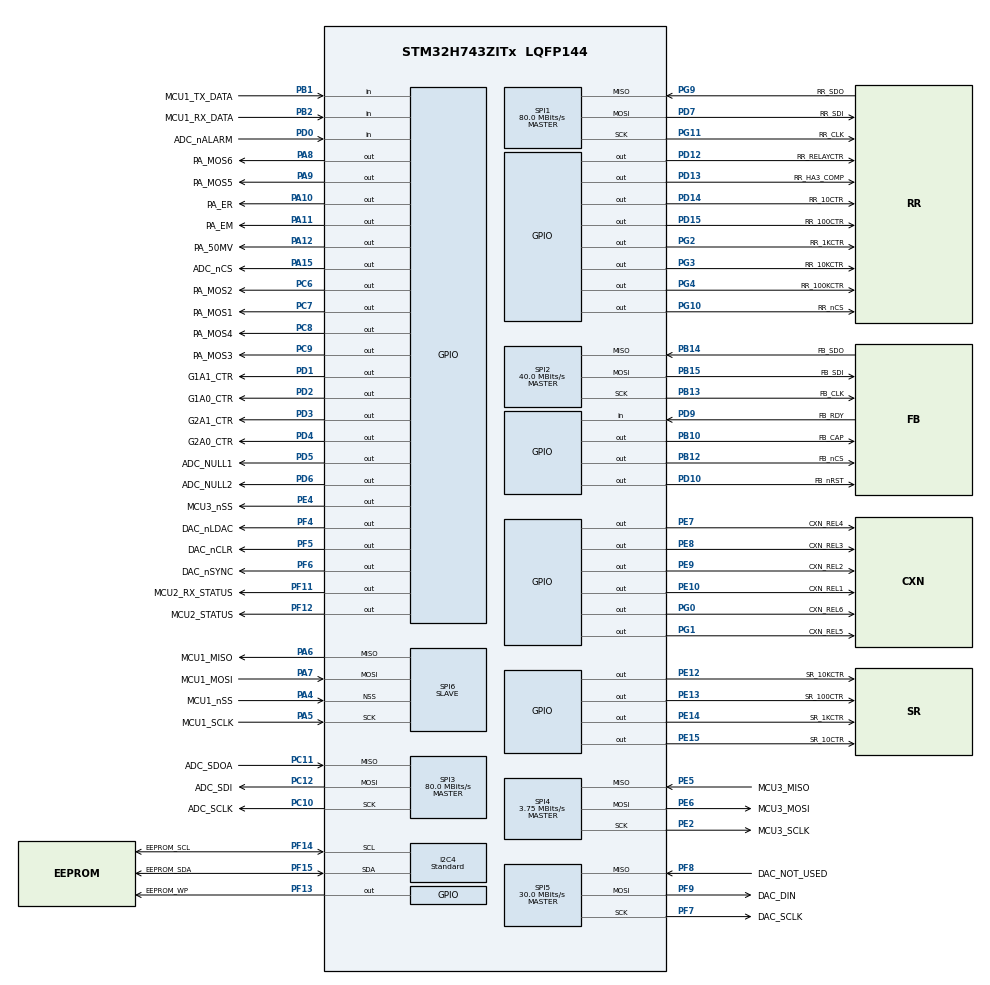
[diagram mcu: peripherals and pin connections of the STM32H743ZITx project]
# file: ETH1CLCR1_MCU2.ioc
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I2C4.I2C_Speed_Mode=I2C_Standard
I2C4.Timing=0x307075B1
Mcu.Family=STM32H7
Mcu.Name=STM32H743ZITx
Mcu.Package=LQFP144
NVIC.PriorityGroup=NVIC_PRIORITYGROUP_4
NVIC.SPI6_IRQn=true\:1\:0\:true\:false\:true\:true\:true
PA10.GPIO_Label=PA_ER
PA10.GPIO_Speed=GPIO_SPEED_FREQ_HIGH
PA10.Signal=GPIO_Output
PA11.GPIO_Label=PA_EM
PA11.GPIO_Speed=GPIO_SPEED_FREQ_HIGH
PA11.Signal=GPIO_Output
PA12.GPIO_Label=PA_50MV
PA12.GPIO_Speed=GPIO_SPEED_FREQ_HIGH
PA12.Signal=GPIO_Output
PA13\ (JTMS/SWDIO).Mode=Serial_Wire
PA13\ (JTMS/SWDIO).Signal=DEBUG_JTMS-SWDIO
PA14\ (JTCK/SWCLK).Mode=Serial_Wire
PA14\ (JTCK/SWCLK).Signal=DEBUG_JTCK-SWCLK
PA15\ (JTDI).GPIO_Label=ADC_nCS
PA15\ (JTDI).GPIO_Speed=GPIO_SPEED_FREQ_VERY_HIGH
PA15\ (JTDI).PinState=GPIO_PIN_SET
PA15\ (JTDI).Signal=GPIO_Output
PA4.GPIO_Label=MCU1_nSS
PA4.GPIO_Speed=GPIO_SPEED_FREQ_HIGH
PA4.Mode=NSS_Signal_Hard_Input
PA4.Signal=SPI6_NSS
PA5.GPIO_Label=MCU1_SCLK
PA5.GPIO_PuPd=GPIO_NOPULL
PA5.GPIO_Speed=GPIO_SPEED_FREQ_HIGH
PA5.Mode=Full_Duplex_Slave
PA5.Signal=SPI6_SCK
PA6.GPIO_Label=MCU1_MISO
PA6.GPIO_Speed=GPIO_SPEED_FREQ_HIGH
PA6.Mode=Full_Duplex_Slave
PA6.Signal=SPI6_MISO
PA7.GPIO_Label=MCU1_MOSI
PA7.GPIO_Speed=GPIO_SPEED_FREQ_HIGH
PA7.Mode=Full_Duplex_Slave
PA7.Signal=SPI6_MOSI
PA8.GPIO_Label=PA_MOS6
PA8.GPIO_Speed=GPIO_SPEED_FREQ_HIGH
PA8.Signal=GPIO_Output
PA9.GPIO_Label=PA_MOS5
PA9.GPIO_Speed=GPIO_SPEED_FREQ_HIGH
PA9.Signal=GPIO_Output
PB1.GPIO_Label=MCU1_TX_DATA
PB1.GPIO_PuPd=GPIO_PULLUP
PB1.Signal=GPIO_Input
PB10.GPIO_Label=FB_CAP
PB10.GPIO_Speed=GPIO_SPEED_FREQ_HIGH
PB10.Signal=GPIO_Output
PB12.GPIO_Label=FB_nCS
PB12.GPIO_Speed=GPIO_SPEED_FREQ_VERY_HIGH
PB12.PinState=GPIO_PIN_SET
PB12.Signal=GPIO_Output
PB13.GPIO_Label=FB_CLK
PB13.GPIO_Speed=GPIO_SPEED_FREQ_LOW
PB13.Mode=Full_Duplex_Master
PB13.Signal=SPI2_SCK
PB14.GPIO_Label=FB_SDO
PB14.GPIO_Speed=GPIO_SPEED_FREQ_LOW
PB14.Mode=Full_Duplex_Master
PB14.Signal=SPI2_MISO
PB15.GPIO_Label=FB_SDI
PB15.GPIO_Speed=GPIO_SPEED_FREQ_LOW
PB15.Mode=Full_Duplex_Master
PB15.Signal=SPI2_MOSI
PB2.GPIO_Label=MCU1_RX_DATA
PB2.GPIO_PuPd=GPIO_PULLUP
PB2.Signal=GPIO_Input
PC10.GPIO_Label=ADC_SCLK
PC10.GPIO_PuPd=GPIO_PULLUP
PC10.GPIO_Speed=GPIO_SPEED_FREQ_MEDIUM
PC10.Mode=Full_Duplex_Master
PC10.Signal=SPI3_SCK
PC11.GPIO_Label=ADC_SDOA
PC11.GPIO_PuPd=GPIO_PULLUP
PC11.GPIO_Speed=GPIO_SPEED_FREQ_HIGH
PC11.Mode=Full_Duplex_Master
PC11.Signal=SPI3_MISO
PC12.GPIO_Label=ADC_SDI
PC12.GPIO_PuPd=GPIO_PULLUP
PC12.GPIO_Speed=GPIO_SPEED_FREQ_HIGH
PC12.Mode=Full_Duplex_Master
PC12.Signal=SPI3_MOSI
PC6.GPIO_Label=PA_MOS2
PC6.GPIO_Speed=GPIO_SPEED_FREQ_HIGH
PC6.Signal=GPIO_Output
PC7.GPIO_Label=PA_MOS1
PC7.GPIO_Speed=GPIO_SPEED_FREQ_HIGH
PC7.Signal=GPIO_Output
PC8.GPIO_Label=PA_MOS4
PC8.GPIO_Speed=GPIO_SPEED_FREQ_HIGH
PC8.Signal=GPIO_Output
PC9.GPIO_Label=PA_MOS3
PC9.GPIO_Speed=GPIO_SPEED_FREQ_HIGH
PC9.Signal=GPIO_Output
PD0.GPIO_Label=ADC_nALARM
PD0.Signal=GPIO_Input
PD1.GPIO_Label=G1A1_CTR
PD1.GPIO_Speed=GPIO_SPEED_FREQ_HIGH
PD1.Signal=GPIO_Output
PD10.GPIO_Label=FB_nRST
PD10.GPIO_Speed=GPIO_SPEED_FREQ_HIGH
PD10.PinState=GPIO_PIN_SET
PD10.Signal=GPIO_Output
PD12.GPIO_Label=RR_RELAYCTR
PD12.GPIO_Speed=GPIO_SPEED_FREQ_HIGH
PD12.Signal=GPIO_Output
PD13.GPIO_Label=RR_HA3_COMP
PD13.GPIO_Speed=GPIO_SPEED_FREQ_HIGH
PD13.Signal=GPIO_Output
PD14.GPIO_Label=RR_10CTR
PD14.GPIO_Speed=GPIO_SPEED_FREQ_HIGH
PD14.Signal=GPIO_Output
PD15.GPIO_Label=RR_100CTR
PD15.GPIO_Speed=GPIO_SPEED_FREQ_HIGH
PD15.Signal=GPIO_Output
PD2.GPIO_Label=G1A0_CTR
PD2.GPIO_Speed=GPIO_SPEED_FREQ_HIGH
PD2.Signal=GPIO_Output
PD3.GPIO_Label=G2A1_CTR
PD3.GPIO_Speed=GPIO_SPEED_FREQ_HIGH
PD3.Signal=GPIO_Output
PD4.GPIO_Label=G2A0_CTR
PD4.GPIO_Speed=GPIO_SPEED_FREQ_HIGH
PD4.Signal=GPIO_Output
PD5.GPIO_Label=ADC_NULL1
PD5.GPIO_Speed=GPIO_SPEED_FREQ_HIGH
PD5.Signal=GPIO_Output
PD6.GPIO_Label=ADC_NULL2
PD6.GPIO_Speed=GPIO_SPEED_FREQ_HIGH
PD6.Signal=GPIO_Output
PD7.GPIO_Label=RR_SDI
PD7.GPIO_Speed=GPIO_SPEED_FREQ_LOW
PD7.Mode=Full_Duplex_Master
PD7.Signal=SPI1_MOSI
PD9.GPIO_Label=FB_RDY
PD9.Signal=GPIO_Input
PE10.GPIO_Label=CXN_REL1
PE10.GPIO_Speed=GPIO_SPEED_FREQ_HIGH
PE10.Signal=GPIO_Output
PE12.GPIO_Label=SR_10KCTR
PE12.GPIO_Speed=GPIO_SPEED_FREQ_HIGH
PE12.Signal=GPIO_Output
PE13.GPIO_Label=SR_100CTR
PE13.GPIO_Speed=GPIO_SPEED_FREQ_HIGH
PE13.Signal=GPIO_Output
PE14.GPIO_Label=SR_1KCTR
PE14.GPIO_Speed=GPIO_SPEED_FREQ_HIGH
PE14.Signal=GPIO_Output
PE15.GPIO_Label=SR_10CTR
PE15.GPIO_Speed=GPIO_SPEED_FREQ_HIGH
PE15.Signal=GPIO_Output
PE2.GPIO_Label=MCU3_SCLK
PE2.GPIO_Speed=GPIO_SPEED_FREQ_HIGH
PE2.Mode=Full_Duplex_Master
PE2.Signal=SPI4_SCK
PE4.GPIO_Label=MCU3_nSS
PE4.GPIO_Speed=GPIO_SPEED_FREQ_HIGH
PE4.PinState=GPIO_PIN_SET
PE4.Signal=GPIO_Output
PE5.GPIO_Label=MCU3_MISO
PE5.GPIO_PuPd=GPIO_PULLUP
PE5.GPIO_Speed=GPIO_SPEED_FREQ_HIGH
PE5.Mode=Full_Duplex_Master
PE5.Signal=SPI4_MISO
PE6.GPIO_Label=MCU3_MOSI
PE6.GPIO_Speed=GPIO_SPEED_FREQ_HIGH
PE6.Mode=Full_Duplex_Master
PE6.Signal=SPI4_MOSI
PE7.GPIO_Label=CXN_REL4
PE7.GPIO_Speed=GPIO_SPEED_FREQ_HIGH
PE7.Signal=GPIO_Output
PE8.GPIO_Label=CXN_REL3
PE8.GPIO_Speed=GPIO_SPEED_FREQ_HIGH
PE8.Signal=GPIO_Output
PE9.GPIO_Label=CXN_REL2
PE9.GPIO_Speed=GPIO_SPEED_FREQ_HIGH
PE9.Signal=GPIO_Output
PF11.GPIO_Label=MCU2_RX_STATUS
PF11.GPIO_PuPd=GPIO_PULLUP
PF11.GPIO_Speed=GPIO_SPEED_FREQ_HIGH
PF11.Signal=GPIO_Output
PF12.GPIO_Label=MCU2_STATUS
PF12.GPIO_Speed=GPIO_SPEED_FREQ_HIGH
PF12.Signal=GPIO_Output
PF13.GPIO_Label=EEPROM_WP
PF13.GPIO_Speed=GPIO_SPEED_FREQ_HIGH
PF13.Signal=GPIO_Output
PF14.GPIO_Label=EEPROM_SCL
PF14.Mode=I2C
PF14.Signal=I2C4_SCL
PF15.GPIO_Label=EEPROM_SDA
PF15.Mode=I2C
PF15.Signal=I2C4_SDA
PF4.GPIO_Label=DAC_nLDAC
PF4.GPIO_Speed=GPIO_SPEED_FREQ_HIGH
PF4.Signal=GPIO_Output
PF5.GPIO_Label=DAC_nCLR
PF5.GPIO_Speed=GPIO_SPEED_FREQ_HIGH
PF5.PinState=GPIO_PIN_SET
PF5.Signal=GPIO_Output
PF6.GPIO_Label=DAC_nSYNC
PF6.GPIO_Speed=GPIO_SPEED_FREQ_HIGH
PF6.PinState=GPIO_PIN_SET
PF6.Signal=GPIO_Output
PF7.GPIO_Label=DAC_SCLK
PF7.GPIO_Speed=GPIO_SPEED_FREQ_HIGH
PF7.Mode=Full_Duplex_Master
PF7.Signal=SPI5_SCK
PF8.GPIO_Label=DAC_NOT_USED
PF8.GPIO_Speed=GPIO_SPEED_FREQ_HIGH
PF8.Mode=Full_Duplex_Master
PF8.Signal=SPI5_MISO
PF9.GPIO_Label=DAC_DIN
PF9.GPIO_Speed=GPIO_SPEED_FREQ_HIGH
PF9.Mode=Full_Duplex_Master
PF9.Signal=SPI5_MOSI
PG0.GPIO_Label=CXN_REL6
PG0.GPIO_Speed=GPIO_SPEED_FREQ_HIGH
PG0.Signal=GPIO_Output
PG1.GPIO_Label=CXN_REL5
PG1.GPIO_Speed=GPIO_SPEED_FREQ_HIGH
PG1.Signal=GPIO_Output
PG10.GPIO_Label=RR_nCS
PG10.GPIO_Speed=GPIO_SPEED_FREQ_VERY_HIGH
PG10.PinState=GPIO_PIN_SET
PG10.Signal=GPIO_Output
PG11.GPIO_Label=RR_CLK
PG11.GPIO_Speed=GPIO_SPEED_FREQ_LOW
PG11.Mode=Full_Duplex_Master
PG11.Signal=SPI1_SCK
PG2.GPIO_Label=RR_1KCTR
PG2.GPIO_Speed=GPIO_SPEED_FREQ_HIGH
PG2.Signal=GPIO_Output
PG3.GPIO_Label=RR_10KCTR
PG3.GPIO_Speed=GPIO_SPEED_FREQ_HIGH
PG3.Signal=GPIO_Output
PG4.GPIO_Label=RR_100KCTR
PG4.GPIO_Speed=GPIO_SPEED_FREQ_HIGH
PG4.Signal=GPIO_Output
PG9.GPIO_Label=RR_SDO
PG9.GPIO_Speed=GPIO_SPEED_FREQ_LOW
PG9.Mode=Full_Duplex_Master
PG9.Signal=SPI1_MISO
PH0-OSC_IN\ (PH0).Mode=HSE-External-Oscillator
PH0-OSC_IN\ (PH0).Signal=RCC_OSC_IN
PH1-OSC_OUT\ (PH1).Mode=HSE-External-Oscillator
PH1-OSC_OUT\ (PH1).Signal=RCC_OSC_OUT
ProjectManager.HeapSize=0x200
ProjectManager.StackSize=0x400
ProjectManager.TargetToolchain=STM32CubeIDE
RCC.ADCFreq_Value=320000000
RCC.APB1Freq_Value=120000000
RCC.APB2Freq_Value=120000000
RCC.APB3Freq_Value=120000000
RCC.APB4Freq_Value=120000000
RCC.CortexFreq_Value=480000000
RCC.D1PPRE=RCC_APB3_DIV2
RCC.D2PPRE1=RCC_APB1_DIV2
RCC.D2PPRE2=RCC_APB2_DIV2
RCC.D3PPRE=RCC_APB4_DIV2
RCC.DIVM1=2
RCC.DIVM2=2
RCC.DIVN1=240
RCC.DIVN2=160
RCC.HCLKFreq_Value=240000000
RCC.HPRE=RCC_HCLK_DIV2
RCC.HSE_VALUE=8000000
RCC.PLLSourceVirtual=RCC_PLLSOURCE_HSE
RCC.SPI123CLockSelection=RCC_SPI123CLKSOURCE_PLL2
RCC.SPI6CLockSelection=RCC_SPI6CLKSOURCE_PLL2
RCC.SYSCLKFreq_VALUE=480000000
RCC.SYSCLKSource=RCC_SYSCLKSOURCE_PLLCLK
RCC.USBFreq_Value=480000000
SPI1.BaudRatePrescaler=SPI_BAUDRATEPRESCALER_4
SPI1.CalculateBaudRate=80.0 MBits/s
SPI1.Direction=SPI_DIRECTION_2LINES
SPI1.Mode=SPI_MODE_MASTER
SPI1.VirtualType=VM_MASTER
SPI2.BaudRatePrescaler=SPI_BAUDRATEPRESCALER_8
SPI2.CalculateBaudRate=40.0 MBits/s
SPI2.Direction=SPI_DIRECTION_2LINES
SPI2.Mode=SPI_MODE_MASTER
SPI2.VirtualType=VM_MASTER
SPI3.BaudRatePrescaler=SPI_BAUDRATEPRESCALER_4
SPI3.CLKPhase=SPI_PHASE_2EDGE
SPI3.CLKPolarity=SPI_POLARITY_HIGH
SPI3.CalculateBaudRate=80.0 MBits/s
SPI3.DataSize=SPI_DATASIZE_16BIT
SPI3.Direction=SPI_DIRECTION_2LINES
SPI3.Mode=SPI_MODE_MASTER
SPI3.VirtualType=VM_MASTER
SPI4.BaudRatePrescaler=SPI_BAUDRATEPRESCALER_32
SPI4.CalculateBaudRate=3.75 MBits/s
SPI4.DataSize=SPI_DATASIZE_8BIT
SPI4.Direction=SPI_DIRECTION_2LINES
SPI4.Mode=SPI_MODE_MASTER
SPI4.VirtualType=VM_MASTER
SPI5.BaudRatePrescaler=SPI_BAUDRATEPRESCALER_4
SPI5.CLKPhase=SPI_PHASE_1EDGE
SPI5.CLKPolarity=SPI_POLARITY_LOW
SPI5.CalculateBaudRate=30.0 MBits/s
SPI5.DataSize=SPI_DATASIZE_8BIT
SPI5.Direction=SPI_DIRECTION_2LINES
SPI5.Mode=SPI_MODE_MASTER
SPI5.VirtualType=VM_MASTER
SPI6.DataSize=SPI_DATASIZE_8BIT
SPI6.Direction=SPI_DIRECTION_2LINES
SPI6.MasterReceiverAutoSusp=SPI_MASTER_RX_AUTOSUSP_DISABLE
SPI6.Mode=SPI_MODE_SLAVE
SPI6.VirtualNSS=VM_NSSHARD
SPI6.VirtualType=VM_SLAVE
board=custom

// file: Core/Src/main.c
/* USER CODE BEGIN Header */
/**
  ******************************************************************************
  * @file           : main.c
  * @brief          : Main program body
  ******************************************************************************
  * @attention
  *
  * <h2><center>&copy; Copyright (c) 2020 STMicroelectronics.
  * All rights reserved.</center></h2>
  *
  * This software component is licensed by ST under BSD 3-Clause license,
  * the "License"; You may not use this file except in compliance with the
  * License. You may obtain a copy of the License at:
  *                        opensource.org/licenses/BSD-3-Clause
  *
  ******************************************************************************
  */
/* USER CODE END Header */

#include "main.h"

/* USER CODE BEGIN Includes */
#include <stdio.h>
#include <stdlib.h>
#include <string.h>

#include "relay.h"
#include "ADC.h"
#include "scpi_def.h"
/* USER CODE END Includes */

I2C_HandleTypeDef hi2c4;

/* USER CODE BEGIN PV */
__IO uint8_t SPI6_TxBuffer[SPI6_BUFFOR_SIZE] = {[0 ... SPI6_BUFFOR_SIZE -1] = '\0'};
uint32_t SPI6_NbDataToTransmit = SPI6_BUFFOR_SIZE;
__IO uint16_t SPI6_TransmitIndex = 0;
uint32_t SPI6_TransmitSize = 0;

__IO uint8_t SPI6_RxBuffer[SPI6_BUFFOR_SIZE] = {[0 ... SPI6_BUFFOR_SIZE -1] = '\0'};
__IO uint16_t SPI6_ReceiveIndex = 0;

__IO uint8_t SPI6_XfrCompleteDetect = 0;

__IO uint8_t SPI6_XfrErrorDetect = 0;

/* USER CODE END PV */

void SystemClock_Config(void);
static void MX_GPIO_Init(void);
static void MX_I2C4_Init(void);
static void MX_SPI1_Init(void);
static void MX_SPI2_Init(void);
static void MX_SPI3_Init(void);
static void MX_SPI4_Init(void);
static void MX_SPI5_Init(void);
static void MX_SPI6_Init(void);

/* USER CODE BEGIN 0 */

static void SPI6_ClearTXBuffer()
{
	for(int32_t x = 0; x < SPI6_BUFFOR_SIZE/2; x++)
	{
		SPI6_TxBuffer[x] = '\0';
	}

}

static SPI6_Status SPI6_CheckMode()
{
		if(LL_GPIO_IsInputPinSet(MCU1_RX_DATA_GPIO_Port, MCU1_RX_DATA_Pin))
		{
			return SPI6_MODE_TX;
		}
		else if(LL_GPIO_IsInputPinSet(MCU1_TX_DATA_GPIO_Port, MCU1_TX_DATA_Pin) && (SPI6_ReceiveIndex > 0))
		{
			return SPI6_MODE_RX;
		}

		return SPI6_MODE_NONE;
}

static void SPI6_DataHandler()
{

}

/* USER CODE END 0 */

int main(void)
{
  /* USER CODE BEGIN 1 */
	volatile uint8_t rx_data;
	uint8_t timeout = 0;
	uint32_t start_time = 0, current_time = 0;
  /* USER CODE END 1 */

  /* MCU Configuration--------------------------------------------------------*/

  /* Reset of all peripherals, Initializes the Flash interface and the Systick. */
  HAL_Init();

  /* Configure the system clock */
  SystemClock_Config();

  /* Initialize all configured peripherals */
  MX_GPIO_Init();
  MX_I2C4_Init();
  MX_SPI1_Init();
  MX_SPI2_Init();
  MX_SPI3_Init();
  MX_SPI4_Init();
  MX_SPI5_Init();
  MX_SPI6_Init();
  /* USER CODE BEGIN 2 */
  RELAY_Init();

  LL_SPI_Enable(SPI3);
  LL_SPI_StartMasterTransfer(SPI3);
  LL_SPI_Enable(SPI4);
  LL_SPI_StartMasterTransfer(SPI4);
  LL_SPI_Enable(SPI5);
  LL_SPI_StartMasterTransfer(SPI5);

  SCPI_Init(&scpi_context,
          scpi_commands,
          &scpi_interface,
          scpi_units_def,
          SCPI_IDN1, SCPI_IDN2, SCPI_IDN3, SCPI_IDN4,
          scpi_input_buffer, SCPI_INPUT_BUFFER_LENGTH,
          scpi_error_queue_data, SCPI_ERROR_QUEUE_SIZE);

  ADC_AD7380_Init();
  ADC_PGA103_Gain(AINA, 1);
  ADC_PGA103_Gain(AINB, 1);
  /* USER CODE END 2 */

  /* Infinite loop */
  /* USER CODE BEGIN WHILE */
  LL_GPIO_ResetOutputPin(MCU2_STATUS_GPIO_Port, MCU2_STATUS_Pin);
  LL_GPIO_SetOutputPin(MCU2_RX_STATUS_GPIO_Port, MCU2_RX_STATUS_Pin);

  while (1)
  {

    /* USER CODE END WHILE */
	  HAL_Delay(5);
    /* USER CODE BEGIN 3 */
	  if(SPI6_MODE_RX == SPI6_CheckMode())
	  {
		  LL_GPIO_ResetOutputPin(MCU2_RX_STATUS_GPIO_Port, MCU2_RX_STATUS_Pin);
		  //SPI6_ClearTXBuffer();
		  SCPI_Input(&scpi_context, SPI6_RxBuffer, SPI6_ReceiveIndex);
		  SPI6_TransmitIndex = 0;
		  SPI6_ReceiveIndex = 0;
		  LL_GPIO_SetOutputPin(MCU2_RX_STATUS_GPIO_Port, MCU2_RX_STATUS_Pin);
	  }
	  else if(SPI6_MODE_TX == SPI6_CheckMode())
	  {
		  SPI6_TransmitIndex = 0;
		  SPI6_ReceiveIndex = 0;
		  SPI6_TransmitSize = 0;
		  LL_GPIO_SetOutputPin(MCU2_RX_STATUS_GPIO_Port, MCU2_RX_STATUS_Pin);
	  }
  }
  /* USER CODE END 3 */
}

void SystemClock_Config(void)
{
  RCC_OscInitTypeDef RCC_OscInitStruct = {0};
  RCC_ClkInitTypeDef RCC_ClkInitStruct = {0};
  RCC_PeriphCLKInitTypeDef PeriphClkInitStruct = {0};

  /** Supply configuration update enable
  */
  HAL_PWREx_ConfigSupply(PWR_LDO_SUPPLY);
  /** Configure the main internal regulator output voltage
  */
  __HAL_PWR_VOLTAGESCALING_CONFIG(PWR_REGULATOR_VOLTAGE_SCALE0);

  while(!__HAL_PWR_GET_FLAG(PWR_FLAG_VOSRDY)) {}
  /** Macro to configure the PLL clock source
  */
  __HAL_RCC_PLL_PLLSOURCE_CONFIG(RCC_PLLSOURCE_HSE);
  /** Initializes the CPU, AHB and APB busses clocks
  */
  RCC_OscInitStruct.OscillatorType = RCC_OSCILLATORTYPE_HSE;
  RCC_OscInitStruct.HSEState = RCC_HSE_ON;
  RCC_OscInitStruct.PLL.PLLState = RCC_PLL_ON;
  RCC_OscInitStruct.PLL.PLLSource = RCC_PLLSOURCE_HSE;
  RCC_OscInitStruct.PLL.PLLM = 2;
  RCC_OscInitStruct.PLL.PLLN = 240;
  RCC_OscInitStruct.PLL.PLLP = 2;
  RCC_OscInitStruct.PLL.PLLQ = 2;
  RCC_OscInitStruct.PLL.PLLR = 2;
  RCC_OscInitStruct.PLL.PLLRGE = RCC_PLL1VCIRANGE_2;
  RCC_OscInitStruct.PLL.PLLVCOSEL = RCC_PLL1VCOWIDE;
  RCC_OscInitStruct.PLL.PLLFRACN = 0;
  if (HAL_RCC_OscConfig(&RCC_OscInitStruct) != HAL_OK)
  {
    Error_Handler();
  }
  /** Initializes the CPU, AHB and APB busses clocks
  */
  RCC_ClkInitStruct.ClockType = RCC_CLOCKTYPE_HCLK|RCC_CLOCKTYPE_SYSCLK
                              |RCC_CLOCKTYPE_PCLK1|RCC_CLOCKTYPE_PCLK2
                              |RCC_CLOCKTYPE_D3PCLK1|RCC_CLOCKTYPE_D1PCLK1;
  RCC_ClkInitStruct.SYSCLKSource = RCC_SYSCLKSOURCE_PLLCLK;
  RCC_ClkInitStruct.SYSCLKDivider = RCC_SYSCLK_DIV1;
  RCC_ClkInitStruct.AHBCLKDivider = RCC_HCLK_DIV2;
  RCC_ClkInitStruct.APB3CLKDivider = RCC_APB3_DIV2;
  RCC_ClkInitStruct.APB1CLKDivider = RCC_APB1_DIV2;
  RCC_ClkInitStruct.APB2CLKDivider = RCC_APB2_DIV2;
  RCC_ClkInitStruct.APB4CLKDivider = RCC_APB4_DIV2;

  if (HAL_RCC_ClockConfig(&RCC_ClkInitStruct, FLASH_LATENCY_4) != HAL_OK)
  {
    Error_Handler();
  }
  PeriphClkInitStruct.PeriphClockSelection = RCC_PERIPHCLK_SPI5|RCC_PERIPHCLK_SPI4
                              |RCC_PERIPHCLK_SPI3|RCC_PERIPHCLK_SPI1
                              |RCC_PERIPHCLK_SPI2|RCC_PERIPHCLK_SPI6
                              |RCC_PERIPHCLK_I2C4;
  PeriphClkInitStruct.PLL2.PLL2M = 2;
  PeriphClkInitStruct.PLL2.PLL2N = 160;
  PeriphClkInitStruct.PLL2.PLL2P = 2;
  PeriphClkInitStruct.PLL2.PLL2Q = 2;
  PeriphClkInitStruct.PLL2.PLL2R = 2;
  PeriphClkInitStruct.PLL2.PLL2RGE = RCC_PLL2VCIRANGE_2;
  PeriphClkInitStruct.PLL2.PLL2VCOSEL = RCC_PLL2VCOWIDE;
  PeriphClkInitStruct.PLL2.PLL2FRACN = 0;
  PeriphClkInitStruct.Spi123ClockSelection = RCC_SPI123CLKSOURCE_PLL2;
  PeriphClkInitStruct.Spi45ClockSelection = RCC_SPI45CLKSOURCE_D2PCLK1;
  PeriphClkInitStruct.I2c4ClockSelection = RCC_I2C4CLKSOURCE_D3PCLK1;
  PeriphClkInitStruct.Spi6ClockSelection = RCC_SPI6CLKSOURCE_PLL2;
  if (HAL_RCCEx_PeriphCLKConfig(&PeriphClkInitStruct) != HAL_OK)
  {
    Error_Handler();
  }
}

static void MX_I2C4_Init(void)
{

  hi2c4.Instance = I2C4;
  hi2c4.Init.Timing = 0x307075B1;
  hi2c4.Init.OwnAddress1 = 0;
  hi2c4.Init.AddressingMode = I2C_ADDRESSINGMODE_7BIT;
  hi2c4.Init.DualAddressMode = I2C_DUALADDRESS_DISABLE;
  hi2c4.Init.OwnAddress2 = 0;
  hi2c4.Init.OwnAddress2Masks = I2C_OA2_NOMASK;
  hi2c4.Init.GeneralCallMode = I2C_GENERALCALL_DISABLE;
  hi2c4.Init.NoStretchMode = I2C_NOSTRETCH_DISABLE;
  if (HAL_I2C_Init(&hi2c4) != HAL_OK)
  {
    Error_Handler();
  }
  /** Configure Analogue filter
  */
  if (HAL_I2CEx_ConfigAnalogFilter(&hi2c4, I2C_ANALOGFILTER_ENABLE) != HAL_OK)
  {
    Error_Handler();
  }
  /** Configure Digital filter
  */
  if (HAL_I2CEx_ConfigDigitalFilter(&hi2c4, 0) != HAL_OK)
  {
    Error_Handler();
  }

}

static void MX_SPI1_Init(void)
{

  LL_SPI_InitTypeDef SPI_InitStruct = {0};

  LL_GPIO_InitTypeDef GPIO_InitStruct = {0};

  /* Peripheral clock enable */
  LL_APB2_GRP1_EnableClock(LL_APB2_GRP1_PERIPH_SPI1);

  LL_AHB4_GRP1_EnableClock(LL_AHB4_GRP1_PERIPH_GPIOD);
  LL_AHB4_GRP1_EnableClock(LL_AHB4_GRP1_PERIPH_GPIOG);
  /**SPI1 GPIO Configuration
  PD7   ------> SPI1_MOSI
  PG9   ------> SPI1_MISO
  PG11   ------> SPI1_SCK
  */
  GPIO_InitStruct.Pin = RR_SDI_Pin;
  GPIO_InitStruct.Mode = LL_GPIO_MODE_ALTERNATE;
  GPIO_InitStruct.Speed = LL_GPIO_SPEED_FREQ_LOW;
  GPIO_InitStruct.OutputType = LL_GPIO_OUTPUT_PUSHPULL;
  GPIO_InitStruct.Pull = LL_GPIO_PULL_NO;
  GPIO_InitStruct.Alternate = LL_GPIO_AF_5;
  LL_GPIO_Init(RR_SDI_GPIO_Port, &GPIO_InitStruct);

  GPIO_InitStruct.Pin = RR_SDO_Pin|RR_CLK_Pin;
  GPIO_InitStruct.Mode = LL_GPIO_MODE_ALTERNATE;
  GPIO_InitStruct.Speed = LL_GPIO_SPEED_FREQ_LOW;
  GPIO_InitStruct.OutputType = LL_GPIO_OUTPUT_PUSHPULL;
  GPIO_InitStruct.Pull = LL_GPIO_PULL_NO;
  GPIO_InitStruct.Alternate = LL_GPIO_AF_5;
  LL_GPIO_Init(GPIOG, &GPIO_InitStruct);

  /* SPI1 parameter configuration*/
  SPI_InitStruct.TransferDirection = LL_SPI_FULL_DUPLEX;
  SPI_InitStruct.Mode = LL_SPI_MODE_MASTER;
  SPI_InitStruct.DataWidth = LL_SPI_DATAWIDTH_4BIT;
  SPI_InitStruct.ClockPolarity = LL_SPI_POLARITY_LOW;
  SPI_InitStruct.ClockPhase = LL_SPI_PHASE_1EDGE;
  SPI_InitStruct.NSS = LL_SPI_NSS_SOFT;
  SPI_InitStruct.BaudRate = LL_SPI_BAUDRATEPRESCALER_DIV4;
  SPI_InitStruct.BitOrder = LL_SPI_MSB_FIRST;
  SPI_InitStruct.CRCCalculation = LL_SPI_CRCCALCULATION_DISABLE;
  SPI_InitStruct.CRCPoly = 0x0;
  LL_SPI_Init(SPI1, &SPI_InitStruct);
  LL_SPI_SetStandard(SPI1, LL_SPI_PROTOCOL_MOTOROLA);
  LL_SPI_EnableNSSPulseMgt(SPI1);

}

static void MX_SPI2_Init(void)
{

  LL_SPI_InitTypeDef SPI_InitStruct = {0};

  LL_GPIO_InitTypeDef GPIO_InitStruct = {0};

  /* Peripheral clock enable */
  LL_APB1_GRP1_EnableClock(LL_APB1_GRP1_PERIPH_SPI2);

  LL_AHB4_GRP1_EnableClock(LL_AHB4_GRP1_PERIPH_GPIOB);
  /**SPI2 GPIO Configuration
  PB13   ------> SPI2_SCK
  PB14   ------> SPI2_MISO
  PB15   ------> SPI2_MOSI
  */
  GPIO_InitStruct.Pin = FB_CLK_Pin|FB_SDO_Pin|FB_SDI_Pin;
  GPIO_InitStruct.Mode = LL_GPIO_MODE_ALTERNATE;
  GPIO_InitStruct.Speed = LL_GPIO_SPEED_FREQ_LOW;
  GPIO_InitStruct.OutputType = LL_GPIO_OUTPUT_PUSHPULL;
  GPIO_InitStruct.Pull = LL_GPIO_PULL_NO;
  GPIO_InitStruct.Alternate = LL_GPIO_AF_5;
  LL_GPIO_Init(GPIOB, &GPIO_InitStruct);

  /* SPI2 parameter configuration*/
  SPI_InitStruct.TransferDirection = LL_SPI_FULL_DUPLEX;
  SPI_InitStruct.Mode = LL_SPI_MODE_MASTER;
  SPI_InitStruct.DataWidth = LL_SPI_DATAWIDTH_4BIT;
  SPI_InitStruct.ClockPolarity = LL_SPI_POLARITY_LOW;
  SPI_InitStruct.ClockPhase = LL_SPI_PHASE_1EDGE;
  SPI_InitStruct.NSS = LL_SPI_NSS_SOFT;
  SPI_InitStruct.BaudRate = LL_SPI_BAUDRATEPRESCALER_DIV8;
  SPI_InitStruct.BitOrder = LL_SPI_MSB_FIRST;
  SPI_InitStruct.CRCCalculation = LL_SPI_CRCCALCULATION_DISABLE;
  SPI_InitStruct.CRCPoly = 0x0;
  LL_SPI_Init(SPI2, &SPI_InitStruct);
  LL_SPI_SetStandard(SPI2, LL_SPI_PROTOCOL_MOTOROLA);
  LL_SPI_EnableNSSPulseMgt(SPI2);

}

static void MX_SPI3_Init(void)
{

  LL_SPI_InitTypeDef SPI_InitStruct = {0};

  LL_GPIO_InitTypeDef GPIO_InitStruct = {0};

  /* Peripheral clock enable */
  LL_APB1_GRP1_EnableClock(LL_APB1_GRP1_PERIPH_SPI3);

  LL_AHB4_GRP1_EnableClock(LL_AHB4_GRP1_PERIPH_GPIOC);
  /**SPI3 GPIO Configuration
  PC10   ------> SPI3_SCK
  PC11   ------> SPI3_MISO
  PC12   ------> SPI3_MOSI
  */
  GPIO_InitStruct.Pin = ADC_SCLK_Pin;
  GPIO_InitStruct.Mode = LL_GPIO_MODE_ALTERNATE;
  GPIO_InitStruct.Speed = LL_GPIO_SPEED_FREQ_MEDIUM;
  GPIO_InitStruct.OutputType = LL_GPIO_OUTPUT_PUSHPULL;
  GPIO_InitStruct.Pull = LL_GPIO_PULL_UP;
  GPIO_InitStruct.Alternate = LL_GPIO_AF_6;
  LL_GPIO_Init(ADC_SCLK_GPIO_Port, &GPIO_InitStruct);

  GPIO_InitStruct.Pin = ADC_SDOA_Pin|ADC_SDI_Pin;
  GPIO_InitStruct.Mode = LL_GPIO_MODE_ALTERNATE;
  GPIO_InitStruct.Speed = LL_GPIO_SPEED_FREQ_HIGH;
  GPIO_InitStruct.OutputType = LL_GPIO_OUTPUT_PUSHPULL;
  GPIO_InitStruct.Pull = LL_GPIO_PULL_UP;
  GPIO_InitStruct.Alternate = LL_GPIO_AF_6;
  LL_GPIO_Init(GPIOC, &GPIO_InitStruct);

  /* SPI3 parameter configuration*/
  SPI_InitStruct.TransferDirection = LL_SPI_FULL_DUPLEX;
  SPI_InitStruct.Mode = LL_SPI_MODE_MASTER;
  SPI_InitStruct.DataWidth = LL_SPI_DATAWIDTH_16BIT;
  SPI_InitStruct.ClockPolarity = LL_SPI_POLARITY_HIGH;
  SPI_InitStruct.ClockPhase = LL_SPI_PHASE_2EDGE;
  SPI_InitStruct.NSS = LL_SPI_NSS_SOFT;
  SPI_InitStruct.BaudRate = LL_SPI_BAUDRATEPRESCALER_DIV4;
  SPI_InitStruct.BitOrder = LL_SPI_MSB_FIRST;
  SPI_InitStruct.CRCCalculation = LL_SPI_CRCCALCULATION_DISABLE;
  SPI_InitStruct.CRCPoly = 0x0;
  LL_SPI_Init(SPI3, &SPI_InitStruct);
  LL_SPI_SetStandard(SPI3, LL_SPI_PROTOCOL_MOTOROLA);
  LL_SPI_EnableNSSPulseMgt(SPI3);

}

static void MX_SPI4_Init(void)
{

  LL_SPI_InitTypeDef SPI_InitStruct = {0};

  LL_GPIO_InitTypeDef GPIO_InitStruct = {0};

  /* Peripheral clock enable */
  LL_APB2_GRP1_EnableClock(LL_APB2_GRP1_PERIPH_SPI4);

  LL_AHB4_GRP1_EnableClock(LL_AHB4_GRP1_PERIPH_GPIOE);
  /**SPI4 GPIO Configuration
  PE2   ------> SPI4_SCK
  PE5   ------> SPI4_MISO
  PE6   ------> SPI4_MOSI
  */
  GPIO_InitStruct.Pin = MCU3_SCLK_Pin|MCU3_MOSI_Pin;
  GPIO_InitStruct.Mode = LL_GPIO_MODE_ALTERNATE;
  GPIO_InitStruct.Speed = LL_GPIO_SPEED_FREQ_HIGH;
  GPIO_InitStruct.OutputType = LL_GPIO_OUTPUT_PUSHPULL;
  GPIO_InitStruct.Pull = LL_GPIO_PULL_NO;
  GPIO_InitStruct.Alternate = LL_GPIO_AF_5;
  LL_GPIO_Init(GPIOE, &GPIO_InitStruct);

  GPIO_InitStruct.Pin = MCU3_MISO_Pin;
  GPIO_InitStruct.Mode = LL_GPIO_MODE_ALTERNATE;
  GPIO_InitStruct.Speed = LL_GPIO_SPEED_FREQ_HIGH;
  GPIO_InitStruct.OutputType = LL_GPIO_OUTPUT_PUSHPULL;
  GPIO_InitStruct.Pull = LL_GPIO_PULL_UP;
  GPIO_InitStruct.Alternate = LL_GPIO_AF_5;
  LL_GPIO_Init(MCU3_MISO_GPIO_Port, &GPIO_InitStruct);

  /* SPI4 parameter configuration*/
  SPI_InitStruct.TransferDirection = LL_SPI_FULL_DUPLEX;
  SPI_InitStruct.Mode = LL_SPI_MODE_MASTER;
  SPI_InitStruct.DataWidth = LL_SPI_DATAWIDTH_8BIT;
  SPI_InitStruct.ClockPolarity = LL_SPI_POLARITY_LOW;
  SPI_InitStruct.ClockPhase = LL_SPI_PHASE_1EDGE;
  SPI_InitStruct.NSS = LL_SPI_NSS_SOFT;
  SPI_InitStruct.BaudRate = LL_SPI_BAUDRATEPRESCALER_DIV32;
  SPI_InitStruct.BitOrder = LL_SPI_MSB_FIRST;
  SPI_InitStruct.CRCCalculation = LL_SPI_CRCCALCULATION_DISABLE;
  SPI_InitStruct.CRCPoly = 0x0;
  LL_SPI_Init(SPI4, &SPI_InitStruct);
  LL_SPI_SetStandard(SPI4, LL_SPI_PROTOCOL_MOTOROLA);
  LL_SPI_EnableNSSPulseMgt(SPI4);

}

static void MX_SPI5_Init(void)
{

  LL_SPI_InitTypeDef SPI_InitStruct = {0};

  LL_GPIO_InitTypeDef GPIO_InitStruct = {0};

  /* Peripheral clock enable */
  LL_APB2_GRP1_EnableClock(LL_APB2_GRP1_PERIPH_SPI5);

  LL_AHB4_GRP1_EnableClock(LL_AHB4_GRP1_PERIPH_GPIOF);
  /**SPI5 GPIO Configuration
  PF7   ------> SPI5_SCK
  PF8   ------> SPI5_MISO
  PF9   ------> SPI5_MOSI
  */
  GPIO_InitStruct.Pin = DAC_SCLK_Pin|DAC_NOT_USED_Pin|DAC_DIN_Pin;
  GPIO_InitStruct.Mode = LL_GPIO_MODE_ALTERNATE;
  GPIO_InitStruct.Speed = LL_GPIO_SPEED_FREQ_HIGH;
  GPIO_InitStruct.OutputType = LL_GPIO_OUTPUT_PUSHPULL;
  GPIO_InitStruct.Pull = LL_GPIO_PULL_NO;
  GPIO_InitStruct.Alternate = LL_GPIO_AF_5;
  LL_GPIO_Init(GPIOF, &GPIO_InitStruct);

  /* SPI5 parameter configuration*/
  SPI_InitStruct.TransferDirection = LL_SPI_FULL_DUPLEX;
  SPI_InitStruct.Mode = LL_SPI_MODE_MASTER;
  SPI_InitStruct.DataWidth = LL_SPI_DATAWIDTH_8BIT;
  SPI_InitStruct.ClockPolarity = LL_SPI_POLARITY_LOW;
  SPI_InitStruct.ClockPhase = LL_SPI_PHASE_1EDGE;
  SPI_InitStruct.NSS = LL_SPI_NSS_SOFT;
  SPI_InitStruct.BaudRate = LL_SPI_BAUDRATEPRESCALER_DIV4;
  SPI_InitStruct.BitOrder = LL_SPI_MSB_FIRST;
  SPI_InitStruct.CRCCalculation = LL_SPI_CRCCALCULATION_DISABLE;
  SPI_InitStruct.CRCPoly = 0x0;
  LL_SPI_Init(SPI5, &SPI_InitStruct);
  LL_SPI_SetStandard(SPI5, LL_SPI_PROTOCOL_MOTOROLA);
  LL_SPI_EnableNSSPulseMgt(SPI5);

}

static void MX_SPI6_Init(void)
{

  LL_SPI_InitTypeDef SPI_InitStruct = {0};

  LL_GPIO_InitTypeDef GPIO_InitStruct = {0};

  /* Peripheral clock enable */
  LL_APB4_GRP1_EnableClock(LL_APB4_GRP1_PERIPH_SPI6);

  LL_AHB4_GRP1_EnableClock(LL_AHB4_GRP1_PERIPH_GPIOA);
  /**SPI6 GPIO Configuration
  PA4   ------> SPI6_NSS
  PA5   ------> SPI6_SCK
  PA6   ------> SPI6_MISO
  PA7   ------> SPI6_MOSI
  */
  GPIO_InitStruct.Pin = MCU1_nSS_Pin|MCU1_SCLK_Pin|MCU1_MISO_Pin|MCU1_MOSI_Pin;
  GPIO_InitStruct.Mode = LL_GPIO_MODE_ALTERNATE;
  GPIO_InitStruct.Speed = LL_GPIO_SPEED_FREQ_HIGH;
  GPIO_InitStruct.OutputType = LL_GPIO_OUTPUT_PUSHPULL;
  GPIO_InitStruct.Pull = LL_GPIO_PULL_NO;
  GPIO_InitStruct.Alternate = LL_GPIO_AF_8;
  LL_GPIO_Init(GPIOA, &GPIO_InitStruct);

  /* SPI6 interrupt Init */
  NVIC_SetPriority(SPI6_IRQn, NVIC_EncodePriority(NVIC_GetPriorityGrouping(),1, 0));
  NVIC_EnableIRQ(SPI6_IRQn);

  /* SPI6 parameter configuration*/
  SPI_InitStruct.TransferDirection = LL_SPI_FULL_DUPLEX;
  SPI_InitStruct.Mode = LL_SPI_MODE_SLAVE;
  SPI_InitStruct.DataWidth = LL_SPI_DATAWIDTH_8BIT;
  SPI_InitStruct.ClockPolarity = LL_SPI_POLARITY_LOW;
  SPI_InitStruct.ClockPhase = LL_SPI_PHASE_1EDGE;
  SPI_InitStruct.NSS = LL_SPI_NSS_HARD_INPUT;
  SPI_InitStruct.BitOrder = LL_SPI_MSB_FIRST;
  SPI_InitStruct.CRCCalculation = LL_SPI_CRCCALCULATION_DISABLE;
  SPI_InitStruct.CRCPoly = 0x0;
  LL_SPI_Init(SPI6, &SPI_InitStruct);
  LL_SPI_SetStandard(SPI6, LL_SPI_PROTOCOL_MOTOROLA);
  LL_SPI_DisableNSSPulseMgt(SPI6);
  /* USER CODE BEGIN SPI6_Init 2 */
  /* Lock GPIO for master to avoid glitches on the clock output */
  LL_SPI_DisableGPIOControl(SPI6);
  LL_SPI_DisableMasterRxAutoSuspend(SPI6);

  /* Set number of date to transmit */
  LL_SPI_SetTransferSize(SPI6, 0);

  /* Enable SPI6 */
  LL_SPI_Enable(SPI6);

  /* Enable RXP Interrupt */
  LL_SPI_EnableIT_RXP(SPI6);
  LL_SPI_EnableIT_TXP(SPI6);
  LL_SPI_EnableIT_UDR(SPI6);
  LL_SPI_EnableIT_EOT(SPI6);

 /* Enable TXP Interrupt */

  /* USER CODE END SPI6_Init 2 */

}

static void MX_GPIO_Init(void)
{
  LL_GPIO_InitTypeDef GPIO_InitStruct = {0};

  /* GPIO Ports Clock Enable */
  LL_AHB4_GRP1_EnableClock(LL_AHB4_GRP1_PERIPH_GPIOE);
  LL_AHB4_GRP1_EnableClock(LL_AHB4_GRP1_PERIPH_GPIOF);
  LL_AHB4_GRP1_EnableClock(LL_AHB4_GRP1_PERIPH_GPIOH);
  LL_AHB4_GRP1_EnableClock(LL_AHB4_GRP1_PERIPH_GPIOA);
  LL_AHB4_GRP1_EnableClock(LL_AHB4_GRP1_PERIPH_GPIOB);
  LL_AHB4_GRP1_EnableClock(LL_AHB4_GRP1_PERIPH_GPIOG);
  LL_AHB4_GRP1_EnableClock(LL_AHB4_GRP1_PERIPH_GPIOD);
  LL_AHB4_GRP1_EnableClock(LL_AHB4_GRP1_PERIPH_GPIOC);

  /**/
  LL_GPIO_SetOutputPin(MCU3_nSS_GPIO_Port, MCU3_nSS_Pin);

  /**/
  LL_GPIO_SetOutputPin(GPIOF, DAC_nCLR_Pin|DAC_nSYNC_Pin);

  /**/
  LL_GPIO_SetOutputPin(FB_nCS_GPIO_Port, FB_nCS_Pin);

  /**/
  LL_GPIO_SetOutputPin(FB_nRST_GPIO_Port, FB_nRST_Pin);

  /**/
  LL_GPIO_SetOutputPin(ADC_nCS_GPIO_Port, ADC_nCS_Pin);

  /**/
  LL_GPIO_SetOutputPin(RR_nCS_GPIO_Port, RR_nCS_Pin);

  /**/
  LL_GPIO_ResetOutputPin(GPIOF, DAC_nLDAC_Pin|MCU2_RX_STATUS_Pin|MCU2_STATUS_Pin|EEPROM_WP_Pin);

  /**/
  LL_GPIO_ResetOutputPin(GPIOG, CXN_REL6_Pin|CXN_REL5_Pin|RR_1KCTR_Pin|RR_10KCTR_Pin
                          |RR_100KCTR_Pin);

  /**/
  LL_GPIO_ResetOutputPin(GPIOE, CXN_REL4_Pin|CXN_REL3_Pin|CXN_REL2_Pin|CXN_REL1_Pin
                          |SR_10KCTR_Pin|SR_100CTR_Pin|SR_1KCTR_Pin|SR_10CTR_Pin);

  /**/
  LL_GPIO_ResetOutputPin(FB_CAP_GPIO_Port, FB_CAP_Pin);

  /**/
  LL_GPIO_ResetOutputPin(GPIOD, RR_RELAYCTR_Pin|RR_HA3_COMP_Pin|RR_10CTR_Pin|RR_100CTR_Pin
                          |G1A1_CTR_Pin|G1A0_CTR_Pin|G2A1_CTR_Pin|G2A0_CTR_Pin
                          |ADC_NULL1_Pin|ADC_NULL2_Pin);

  /**/
  LL_GPIO_ResetOutputPin(GPIOC, PA_MOS2_Pin|PA_MOS1_Pin|PA_MOS4_Pin|PA_MOS3_Pin);

  /**/
  LL_GPIO_ResetOutputPin(GPIOA, PA_MOS6_Pin|PA_MOS5_Pin|PA_ER_Pin|PA_EM_Pin
                          |PA_50MV_Pin);

  /**/
  GPIO_InitStruct.Pin = MCU3_nSS_Pin|CXN_REL4_Pin|CXN_REL3_Pin|CXN_REL2_Pin
                          |CXN_REL1_Pin|SR_10KCTR_Pin|SR_100CTR_Pin|SR_1KCTR_Pin
                          |SR_10CTR_Pin;
  GPIO_InitStruct.Mode = LL_GPIO_MODE_OUTPUT;
  GPIO_InitStruct.Speed = LL_GPIO_SPEED_FREQ_HIGH;
  GPIO_InitStruct.OutputType = LL_GPIO_OUTPUT_PUSHPULL;
  GPIO_InitStruct.Pull = LL_GPIO_PULL_NO;
  LL_GPIO_Init(GPIOE, &GPIO_InitStruct);

  /**/
  GPIO_InitStruct.Pin = DAC_nLDAC_Pin|DAC_nCLR_Pin|DAC_nSYNC_Pin|MCU2_STATUS_Pin
                          |EEPROM_WP_Pin;
  GPIO_InitStruct.Mode = LL_GPIO_MODE_OUTPUT;
  GPIO_InitStruct.Speed = LL_GPIO_SPEED_FREQ_HIGH;
  GPIO_InitStruct.OutputType = LL_GPIO_OUTPUT_PUSHPULL;
  GPIO_InitStruct.Pull = LL_GPIO_PULL_NO;
  LL_GPIO_Init(GPIOF, &GPIO_InitStruct);

  /**/
  GPIO_InitStruct.Pin = MCU1_TX_DATA_Pin|MCU1_RX_DATA_Pin;
  GPIO_InitStruct.Mode = LL_GPIO_MODE_INPUT;
  GPIO_InitStruct.Pull = LL_GPIO_PULL_UP;
  LL_GPIO_Init(GPIOB, &GPIO_InitStruct);

  /**/
  GPIO_InitStruct.Pin = MCU2_RX_STATUS_Pin;
  GPIO_InitStruct.Mode = LL_GPIO_MODE_OUTPUT;
  GPIO_InitStruct.Speed = LL_GPIO_SPEED_FREQ_HIGH;
  GPIO_InitStruct.OutputType = LL_GPIO_OUTPUT_PUSHPULL;
  GPIO_InitStruct.Pull = LL_GPIO_PULL_UP;
  LL_GPIO_Init(MCU2_RX_STATUS_GPIO_Port, &GPIO_InitStruct);

  /**/
  GPIO_InitStruct.Pin = CXN_REL6_Pin|CXN_REL5_Pin|RR_1KCTR_Pin|RR_10KCTR_Pin
                          |RR_100KCTR_Pin;
  GPIO_InitStruct.Mode = LL_GPIO_MODE_OUTPUT;
  GPIO_InitStruct.Speed = LL_GPIO_SPEED_FREQ_HIGH;
  GPIO_InitStruct.OutputType = LL_GPIO_OUTPUT_PUSHPULL;
  GPIO_InitStruct.Pull = LL_GPIO_PULL_NO;
  LL_GPIO_Init(GPIOG, &GPIO_InitStruct);

  /**/
  GPIO_InitStruct.Pin = FB_CAP_Pin;
  GPIO_InitStruct.Mode = LL_GPIO_MODE_OUTPUT;
  GPIO_InitStruct.Speed = LL_GPIO_SPEED_FREQ_HIGH;
  GPIO_InitStruct.OutputType = LL_GPIO_OUTPUT_PUSHPULL;
  GPIO_InitStruct.Pull = LL_GPIO_PULL_NO;
  LL_GPIO_Init(FB_CAP_GPIO_Port, &GPIO_InitStruct);

  /**/
  GPIO_InitStruct.Pin = FB_nCS_Pin;
  GPIO_InitStruct.Mode = LL_GPIO_MODE_OUTPUT;
  GPIO_InitStruct.Speed = LL_GPIO_SPEED_FREQ_VERY_HIGH;
  GPIO_InitStruct.OutputType = LL_GPIO_OUTPUT_PUSHPULL;
  GPIO_InitStruct.Pull = LL_GPIO_PULL_NO;
  LL_GPIO_Init(FB_nCS_GPIO_Port, &GPIO_InitStruct);

  /**/
  GPIO_InitStruct.Pin = FB_RDY_Pin|ADC_nALARM_Pin;
  GPIO_InitStruct.Mode = LL_GPIO_MODE_INPUT;
  GPIO_InitStruct.Pull = LL_GPIO_PULL_NO;
  LL_GPIO_Init(GPIOD, &GPIO_InitStruct);

  /**/
  GPIO_InitStruct.Pin = FB_nRST_Pin|RR_RELAYCTR_Pin|RR_HA3_COMP_Pin|RR_10CTR_Pin
                          |RR_100CTR_Pin|G1A1_CTR_Pin|G1A0_CTR_Pin|G2A1_CTR_Pin
                          |G2A0_CTR_Pin|ADC_NULL1_Pin|ADC_NULL2_Pin;
  GPIO_InitStruct.Mode = LL_GPIO_MODE_OUTPUT;
  GPIO_InitStruct.Speed = LL_GPIO_SPEED_FREQ_HIGH;
  GPIO_InitStruct.OutputType = LL_GPIO_OUTPUT_PUSHPULL;
  GPIO_InitStruct.Pull = LL_GPIO_PULL_NO;
  LL_GPIO_Init(GPIOD, &GPIO_InitStruct);

  /**/
  GPIO_InitStruct.Pin = PA_MOS2_Pin|PA_MOS1_Pin|PA_MOS4_Pin|PA_MOS3_Pin;
  GPIO_InitStruct.Mode = LL_GPIO_MODE_OUTPUT;
  GPIO_InitStruct.Speed = LL_GPIO_SPEED_FREQ_HIGH;
  GPIO_InitStruct.OutputType = LL_GPIO_OUTPUT_PUSHPULL;
  GPIO_InitStruct.Pull = LL_GPIO_PULL_NO;
  LL_GPIO_Init(GPIOC, &GPIO_InitStruct);

  /**/
  GPIO_InitStruct.Pin = PA_MOS6_Pin|PA_MOS5_Pin|PA_ER_Pin|PA_EM_Pin
                          |PA_50MV_Pin;
  GPIO_InitStruct.Mode = LL_GPIO_MODE_OUTPUT;
  GPIO_InitStruct.Speed = LL_GPIO_SPEED_FREQ_HIGH;
  GPIO_InitStruct.OutputType = LL_GPIO_OUTPUT_PUSHPULL;
  GPIO_InitStruct.Pull = LL_GPIO_PULL_NO;
  LL_GPIO_Init(GPIOA, &GPIO_InitStruct);

  /**/
  GPIO_InitStruct.Pin = ADC_nCS_Pin;
  GPIO_InitStruct.Mode = LL_GPIO_MODE_OUTPUT;
  GPIO_InitStruct.Speed = LL_GPIO_SPEED_FREQ_VERY_HIGH;
  GPIO_InitStruct.OutputType = LL_GPIO_OUTPUT_PUSHPULL;
  GPIO_InitStruct.Pull = LL_GPIO_PULL_NO;
  LL_GPIO_Init(ADC_nCS_GPIO_Port, &GPIO_InitStruct);

  /**/
  GPIO_InitStruct.Pin = RR_nCS_Pin;
  GPIO_InitStruct.Mode = LL_GPIO_MODE_OUTPUT;
  GPIO_InitStruct.Speed = LL_GPIO_SPEED_FREQ_VERY_HIGH;
  GPIO_InitStruct.OutputType = LL_GPIO_OUTPUT_PUSHPULL;
  GPIO_InitStruct.Pull = LL_GPIO_PULL_NO;
  LL_GPIO_Init(RR_nCS_GPIO_Port, &GPIO_InitStruct);

}

void Error_Handler(void)
{
}

/************************ (C) COPYRIGHT STMicroelectronics *****END OF FILE****/
